# IMM100A register map
Vendor: Infineon; File version: 0.8.0 (Reference Manual v0.8.0)
CPU: CM0 r0p0, little endian, no MPU, no FPU, 2 interrupt priority bits
Registers are 32-bit, read-write, reset 0x0 unless marked. A register's access mark holds for its fields unless they carry their own. Offsets are from the block's base; [hi:lo] are bit positions; {n}, {i} and the like mark numbered series; 'fields as' and 'values as' point back to an identical list.

## USIC0 — Universal Serial Interface Controller 0
Base 0x48000008
Same registers: USIC1 0x48004008
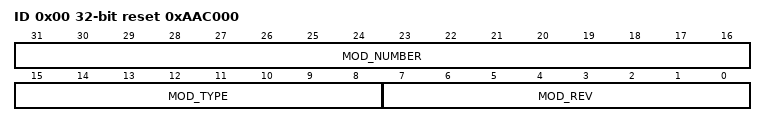
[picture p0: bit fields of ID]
0x00 ID ro reset 0xAAC000 (reset mask 0xFFFFFF00) — Module Identification Register
  [31:16] MOD_NUMBER — Module Number Value
  [15:8] MOD_TYPE — Module Type
  [7:0] MOD_REV — Module Revision Number

## CAN — Controller Area Networks
Base 0x50040000
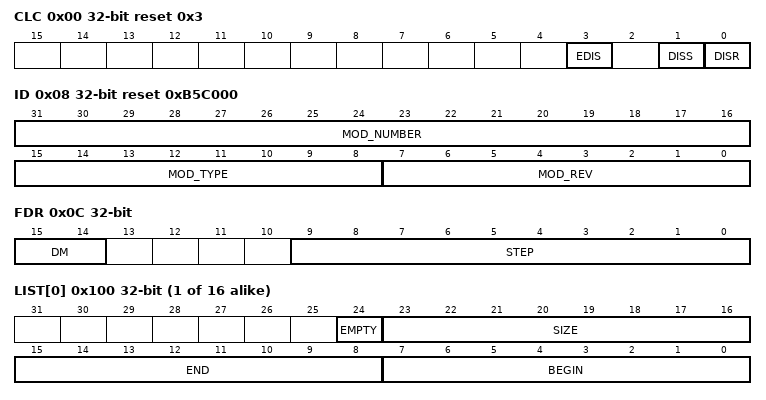
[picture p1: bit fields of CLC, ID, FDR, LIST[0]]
0x00 CLC access per field reset 0x3 — CAN Clock Control Register
  [3] EDIS rw — Sleep Mode Enable Control
  [1] DISS ro — Module Disable Status Bit
  [0] DISR rw — Module Disable Request Bit
0x08 ID ro reset 0xB5C000 (reset mask 0xFFFFFF00) — Module Identification Register
  [31:16] MOD_NUMBER — Module Number Value
  [15:8] MOD_TYPE — Module Type
    192=Define the module as a 32-bit module
  [7:0] MOD_REV — Module Revision Number
0x0C FDR — CAN Fractional Divider Register
  [15:14] DM — Divider Mode
  [9:0] STEP — Step Value
{0x100+4i} LIST[{i}] (i=0..15) ro reset not defined
  [24] EMPTY — List Empty Indication
    0=At least one message object is allocated to list i; 1=No message object is allocated to the list i. List i is empty.
  [23:16] SIZE — List Size
  [15:8] END — List End
  [7:0] BEGIN — List Begin
{0x140+4i} MSPND[{i}] (i=0..7) — Message Pending Register
  [31:0] PND — Message Pending
{0x180+4i} MSID[{i}] (i=0..7) ro reset 0x20 — Message Index Register
  [5:0] INDEX — Message Pending Index
0x1C0 MSIMASK — Message Index Mask Register
  [31:0] IM — Message Index Mask
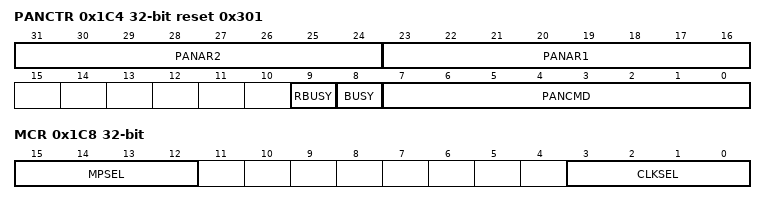
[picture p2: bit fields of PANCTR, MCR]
0x1C4 PANCTR access per field reset 0x301 — Panel Control Register
  [31:24] PANAR2 rw — Panel Argument 2
  [23:16] PANAR1 rw — Panel Argument 1
  [9] RBUSY ro — Result Busy Flag
    0=No update of PANAR1 and PANAR2 is scheduled by the list controller; 1=A list command is running (BUSY = 1) that will write results to PANAR1 and PANAR2, but the results are not yet available
  [8] BUSY ro — Panel Busy Flag
    0=Panel has finished command and is ready to accept a new command; 1=Panel operation is in progress
  [7:0] PANCMD rw — Panel Command
0x1C8 MCR — Module Control Register
  [15:12] MPSEL — Message Pending Selector
  [3:0] CLKSEL — Baud Rate Logic Clock Select
    0=No clock supplied; 1=fMCLK; 2=fOSC_HP; 4=hard wired to 0; 8=hard wired to 0
0x1CC MITR wo — Module Interrupt Trigger Register
  [7:0] IT — Interrupt Trigger

## SCU_GENERAL — System Control Unit
Base 0x40010000
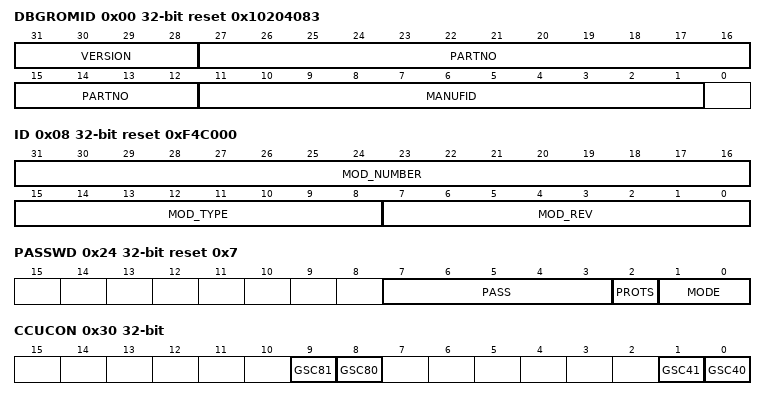
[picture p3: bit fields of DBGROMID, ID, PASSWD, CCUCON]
0x00 DBGROMID ro reset 0x10204083 — Debug System ROM ID Register
  [31:28] VERSION — Product version
  [27:12] PARTNO — Part Number
  [11:1] MANUFID — Manufactory Identity
0x04 IDCHIP ro — Chip ID Register
  [31:0] IDCHIP — CHIP ID
0x08 ID ro reset 0xF4C000 (reset mask 0xFFFFFF00) — SCU Module ID Register
  [31:16] MOD_NUMBER — Module Number Value
  [15:8] MOD_TYPE — Module Type
  [7:0] MOD_REV — Module Revision Number
0x14 SSW0 — SSW Register 0
  [31:0] DAT — SSW Data
0x24 PASSWD access per field reset 0x7 — Password Register
  [7:3] PASS wo — Password Bits
    24=Enables writing of the bit field MODE; 19=Opens access to writing of all protected bits; 21=Closes access to writing of all protected bits
  [2] PROTS ro — Bit Protection Signal Status Bit
    0=Software is able to write to all protected bits; 1=Software is unable to write to any of the protected bits
  [1:0] MODE rw — Bit Protection Scheme Control Bits
    0=Scheme disabled - direct access to the protected bits is allowed; 3=Scheme enabled - the bit field PASS has to be written with the passwords to open and close the access to the protected bits. (Default)
0x30 CCUCON — CCU Control Register
  [9] GSC81 — Global Start Control CCU81
  [8] GSC80 — Global Start Control CCU80
  [1] GSC41 — Global Start Control CCU41
  [0] GSC40 — Global Start Control CCU40
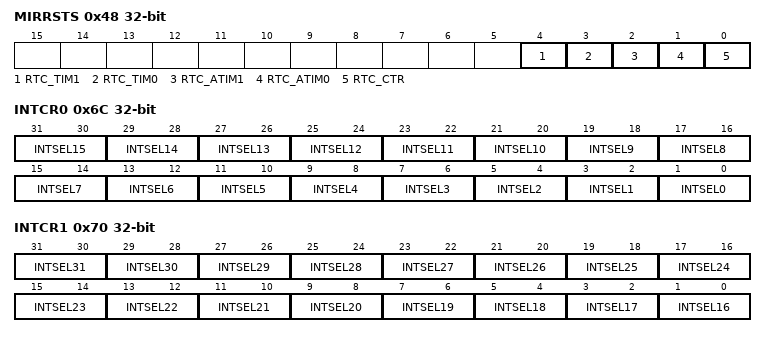
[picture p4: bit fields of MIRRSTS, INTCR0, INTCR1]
0x48 MIRRSTS ro — Mirror Update Status Register
  [4] RTC_TIM1 — RTC TIM1 Mirror Register Update Status
  [3] RTC_TIM0 — RTC TIM0 Mirror Register Update Status
  [2] RTC_ATIM1 — RTC ATIM1 Mirror Register Update Status
  [1] RTC_ATIM0 — RTC ATIM0 Mirror Register Update Status
  [0] RTC_CTR — RTC CTR Mirror Register Update Status
0x54 PMTSR — Parity Memory Test Select Register
  [0] MTENS — Parity Test Enable Control for 16kbytes SRAM
    0=standard operation; 1=generate an inverted parity bit during a write operation
0x68 PFUCR reset 0x1 — Prefetch Unit Control Register
  [0] PFUBYP — Prefetch Unit (PFU) Bypass
    0=PFU not bypass; 1=PFU bypass
0x6C INTCR0 — Interrupt Control Register 0
  [all] fields
    0=Select source A; 1=Select source B; 2=Select source C; 3=Select source A or B
  [2n+1:2n] INTSEL{n} (n=0..15) — Interrupt Source Select for Node {n}
0x70 INTCR1 — Interrupt Control Register 1
  [all] fields
    values as the fields of INTCR0
  [2n-31:2n-32] INTSEL{n} (n=16..31) — Interrupt Source Select for Node {n}
0x74 STSTAT ro (reset mask 0xFFFFFFF0) — Startup Status Register
  [1:0] HWCON — HW Configuration
    0=User productive mode (UPM); 1=ASC BSL; 2=Alternate Boot Mode (ABM); 3=CAN BSL
